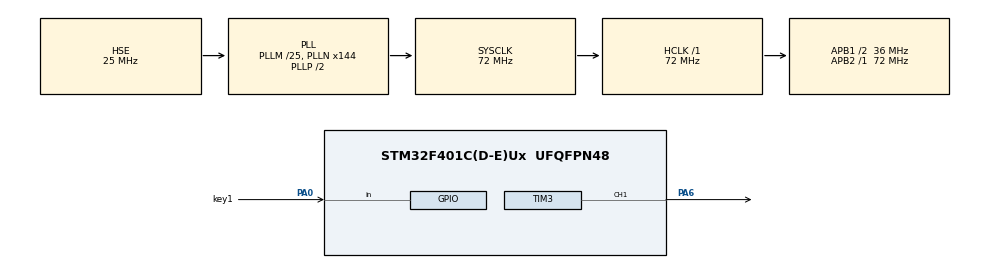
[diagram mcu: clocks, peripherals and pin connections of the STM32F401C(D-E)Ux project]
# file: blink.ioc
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Mcu.Family=STM32F4
Mcu.Name=STM32F401C(D-E)Ux
Mcu.Package=UFQFPN48
NVIC.PriorityGroup=NVIC_PRIORITYGROUP_2
NVIC.RCC_IRQn=true\:0\:0\:false\:false\:true\:true\:false
NVIC.TIM2_IRQn=true\:0\:0\:false\:false\:true\:true\:true
NVIC.TIM3_IRQn=true\:0\:0\:false\:false\:true\:true\:true
PA0-WKUP.GPIO_Label=key1
PA0-WKUP.GPIO_PuPd=GPIO_PULLUP
PA0-WKUP.Signal=GPIO_Input
PA13.Mode=Serial_Wire
PA13.Signal=SYS_JTMS-SWDIO
PA14.Mode=Serial_Wire
PA14.Signal=SYS_JTCK-SWCLK
PA6.Signal=S_TIM3_CH1
PC14-OSC32_IN.Mode=LSE-External-Oscillator
PC14-OSC32_IN.Signal=RCC_OSC32_IN
PC15-OSC32_OUT.Mode=LSE-External-Oscillator
PC15-OSC32_OUT.Signal=RCC_OSC32_OUT
PH0\ -\ OSC_IN.Mode=HSE-External-Oscillator
PH0\ -\ OSC_IN.Signal=RCC_OSC_IN
PH1\ -\ OSC_OUT.Mode=HSE-External-Oscillator
PH1\ -\ OSC_OUT.Signal=RCC_OSC_OUT
ProjectManager.HeapSize=0x200
ProjectManager.StackSize=0x400
ProjectManager.TargetToolchain=MDK-ARM V5.32
RCC.48MHZClocksFreq_Value=36000000
RCC.AHBFreq_Value=72000000
RCC.APB1CLKDivider=RCC_HCLK_DIV2
RCC.APB1Freq_Value=36000000
RCC.APB1TimFreq_Value=72000000
RCC.APB2Freq_Value=72000000
RCC.APB2TimFreq_Value=72000000
RCC.CortexFreq_Value=72000000
RCC.HCLKFreq_Value=72000000
RCC.HSE_VALUE=25000000
RCC.HSI_VALUE=16000000
RCC.PLLM=25
RCC.PLLN=144
RCC.PLLSourceVirtual=RCC_PLLSOURCE_HSE
RCC.SYSCLKFreq_VALUE=72000000
RCC.SYSCLKSource=RCC_SYSCLKSOURCE_PLLCLK
RCC.VCOOutputFreq_Value=144000000
SH.S_TIM3_CH1.0=TIM3_CH1,PWM Generation1 CH1
TIM2.AutoReloadPreload=TIM_AUTORELOAD_PRELOAD_ENABLE
TIM2.Period=999
TIM2.Prescaler=7199
TIM3.AutoReloadPreload=TIM_AUTORELOAD_PRELOAD_ENABLE
TIM3.Channel-PWM\ Generation1\ CH1=TIM_CHANNEL_1
TIM3.OCPolarity_1=TIM_OCPOLARITY_LOW
TIM3.Period=499
TIM3.Prescaler=71
VP_TIM2_VS_ClockSourceINT.Mode=Internal
VP_TIM3_VS_ClockSourceINT.Mode=Internal
board=custom

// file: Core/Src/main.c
/* USER CODE BEGIN Header */
/**
  ******************************************************************************
  * @file           : main.c
  * @brief          : Main program body
  ******************************************************************************
  * @attention
  *
  * Copyright (c) 2022 STMicroelectronics.
  * All rights reserved.
  *
  * This software is licensed under terms that can be found in the LICENSE file
  * in the root directory of this software component.
  * If no LICENSE file comes with this software, it is provided AS-IS.
  *
  ******************************************************************************
  */
/* USER CODE END Header */
#include "main.h"
#include "tim.h"
#include "gpio.h"

/* USER CODE BEGIN PD */
#define led_on __HAL_TIM_SetCompare(&htim3, TIM_CHANNEL_1, 499)
#define led_off __HAL_TIM_SetCompare(&htim3, TIM_CHANNEL_1, 0)
#define key_push HAL_GPIO_ReadPin(key1_GPIO_Port,key1_Pin)==0
#define key_pull HAL_GPIO_ReadPin(key1_GPIO_Port,key1_Pin)==1
/* USER CODE END PD */

void SystemClock_Config(void);

/* USER CODE BEGIN 0 */
uint8_t ModeSet=0;
uint8_t key_state=0;//0:未按下；1：短按；2：短按两次：3：长按
uint16_t pwmVal=50;   //mode2的PWM计数
uint8_t dir=1;
uint16_t counter1=0;//mode1的计数
uint8_t frequence=0;//mode1的闪烁时间

void scan();
void Meun();
void breath();

/* USER CODE END 0 */

int main(void)
{

  /* MCU Configuration--------------------------------------------------------*/

  /* Reset of all peripherals, Initializes the Flash interface and the Systick. */
  HAL_Init();

  /* Configure the system clock */
  SystemClock_Config();

  /* Initialize all configured peripherals */
  MX_GPIO_Init();
  MX_TIM3_Init();
  MX_TIM2_Init();
  /* USER CODE BEGIN 2 */

  HAL_TIM_PWM_Start(&htim3,TIM_CHANNEL_1);//初始化定时器3，用于mode2
	HAL_TIM_Base_Start_IT(&htim2);//初始化定时器2，用于mode1

  /* USER CODE END 2 */

  /* Infinite loop */
  while (1)
  {

    /* USER CODE BEGIN 3 */
		scan();
		HAL_Delay(200);
		Meun();

  }
  /* USER CODE END 3 */
}

void SystemClock_Config(void)
{
  RCC_OscInitTypeDef RCC_OscInitStruct = {0};
  RCC_ClkInitTypeDef RCC_ClkInitStruct = {0};

  /** Configure the main internal regulator output voltage
  */
  __HAL_RCC_PWR_CLK_ENABLE();
  __HAL_PWR_VOLTAGESCALING_CONFIG(PWR_REGULATOR_VOLTAGE_SCALE2);
  /** Initializes the RCC Oscillators according to the specified parameters
  * in the RCC_OscInitTypeDef structure.
  */
  RCC_OscInitStruct.OscillatorType = RCC_OSCILLATORTYPE_HSE;
  RCC_OscInitStruct.HSEState = RCC_HSE_ON;
  RCC_OscInitStruct.PLL.PLLState = RCC_PLL_ON;
  RCC_OscInitStruct.PLL.PLLSource = RCC_PLLSOURCE_HSE;
  RCC_OscInitStruct.PLL.PLLM = 25;
  RCC_OscInitStruct.PLL.PLLN = 144;
  RCC_OscInitStruct.PLL.PLLP = RCC_PLLP_DIV2;
  RCC_OscInitStruct.PLL.PLLQ = 4;
  if (HAL_RCC_OscConfig(&RCC_OscInitStruct) != HAL_OK)
  {
    Error_Handler();
  }
  /** Initializes the CPU, AHB and APB buses clocks
  */
  RCC_ClkInitStruct.ClockType = RCC_CLOCKTYPE_HCLK|RCC_CLOCKTYPE_SYSCLK
                              |RCC_CLOCKTYPE_PCLK1|RCC_CLOCKTYPE_PCLK2;
  RCC_ClkInitStruct.SYSCLKSource = RCC_SYSCLKSOURCE_PLLCLK;
  RCC_ClkInitStruct.AHBCLKDivider = RCC_SYSCLK_DIV1;
  RCC_ClkInitStruct.APB1CLKDivider = RCC_HCLK_DIV2;
  RCC_ClkInitStruct.APB2CLKDivider = RCC_HCLK_DIV1;

  if (HAL_RCC_ClockConfig(&RCC_ClkInitStruct, FLASH_LATENCY_2) != HAL_OK)
  {
    Error_Handler();
  }
}

/* USER CODE BEGIN 4 */
void scan()
{
	if(key_push)
	{
		HAL_Delay(20);//按键消抖
		if(key_push)//第一次按下
		{
			HAL_Delay(200);
			if(key_pull)//中途没有按
			{
				HAL_Delay(20);//按键消抖
				if(key_pull)
				{
					HAL_Delay(300);
					if(key_push)//连续按两次
					{
						HAL_Delay(20);//按键消抖
						if(key_push)
							key_state=2;//按两次
					}else if(key_pull)
						key_state=1;//短按一下
				}
			}	else	if(key_push)//中途按下了
				{
					HAL_Delay(300);
					if(key_push)
						key_state=3;//长按
				}
		}
	}
}

void Meun()
{
//	if(key_state==3)
//		ModeSet=(ModeSet+1)%3;
		switch(ModeSet)
		{
			case 0:
				led_on;
			if(key_state==3)//模式转换
			{
				ModeSet=(ModeSet+1)%3;
				key_state=0;
			}
				break;
			case 1:
				if(counter1<=frequence)
					led_on;
				else
					led_off;
				if(key_state==1)
				{
					frequence=(frequence+1)%10;
					key_state=0;//按键复位
				}else if(key_state==3)//mode转换
				{
					ModeSet=(ModeSet+1)%3;
					key_state=0;
				}
				break;
			case 2:
				led_off;
				breath();
				if(key_state==1)
				{
					if(pwmVal<450)
					{
						pwmVal+=50;
						key_state=0;
						breath();
					}else if(pwmVal>=450)
					{
						pwmVal=50;
						key_state=0;
						breath();
					}
				}else if(key_state==2)
					{
						key_state=0;
						breath();
						if(pwmVal<=60)
						{
							pwmVal=50;//小于50限幅操作
						}else
							pwmVal-=50;
					}else if(key_state==3)
					{
						ModeSet=(ModeSet+1)%3;
						key_state=0;
					}
				break;
			default:
				break;
		}
	}

/*定时器2，每100ms产生一次中断*/
void HAL_TIM_PeriodElapsedCallback(TIM_HandleTypeDef *htim)
{
    if (htim == (&htim2))
    {
			counter1=(counter1+1)%10;
    }
}
void breath()
{
		TIM3->CCR1 = pwmVal;   //改变占空比
	  HAL_Delay(1);

}
/* USER CODE END 4 */

void Error_Handler(void)
{
  __disable_irq();
  while (1)
  {
  }
}
